AUTOSAR XML (schema 4-0-3)
package /ComponentTypes
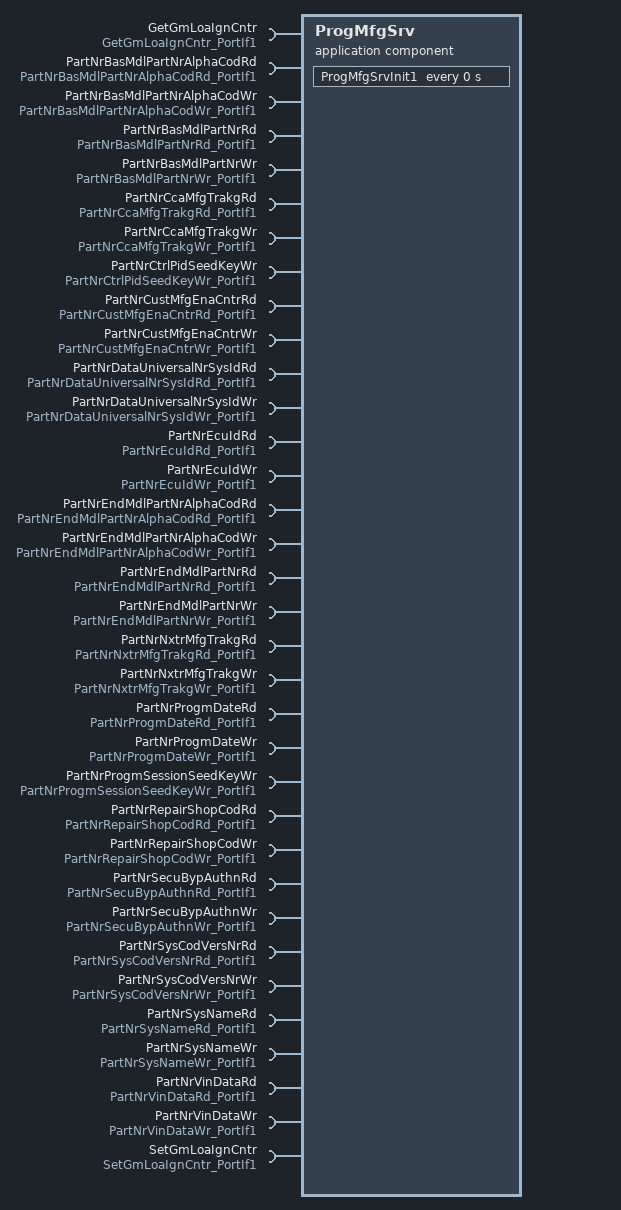
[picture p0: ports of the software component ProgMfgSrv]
  application sw component type ProgMfgSrv
    34 x require port:
      GetGmLoaIgnCntr: required-interface=GetGmLoaIgnCntr_PortIf1
      PartNrBasMdlPartNrAlphaCodRd: required-interface=PartNrBasMdlPartNrAlphaCodRd_PortIf1
      PartNrBasMdlPartNrAlphaCodWr: required-interface=PartNrBasMdlPartNrAlphaCodWr_PortIf1
      PartNrBasMdlPartNrRd: required-interface=PartNrBasMdlPartNrRd_PortIf1
      PartNrBasMdlPartNrWr: required-interface=PartNrBasMdlPartNrWr_PortIf1
      PartNrCcaMfgTrakgRd: required-interface=PartNrCcaMfgTrakgRd_PortIf1
      PartNrCcaMfgTrakgWr: required-interface=PartNrCcaMfgTrakgWr_PortIf1
      PartNrCtrlPidSeedKeyWr: required-interface=PartNrCtrlPidSeedKeyWr_PortIf1
      PartNrCustMfgEnaCntrRd: required-interface=PartNrCustMfgEnaCntrRd_PortIf1
      PartNrCustMfgEnaCntrWr: required-interface=PartNrCustMfgEnaCntrWr_PortIf1
      PartNrDataUniversalNrSysIdRd: required-interface=PartNrDataUniversalNrSysIdRd_PortIf1
      PartNrDataUniversalNrSysIdWr: required-interface=PartNrDataUniversalNrSysIdWr_PortIf1
      PartNrEcuIdRd: required-interface=PartNrEcuIdRd_PortIf1
      PartNrEcuIdWr: required-interface=PartNrEcuIdWr_PortIf1
      PartNrEndMdlPartNrAlphaCodRd: required-interface=PartNrEndMdlPartNrAlphaCodRd_PortIf1
      PartNrEndMdlPartNrAlphaCodWr: required-interface=PartNrEndMdlPartNrAlphaCodWr_PortIf1
      PartNrEndMdlPartNrRd: required-interface=PartNrEndMdlPartNrRd_PortIf1
      PartNrEndMdlPartNrWr: required-interface=PartNrEndMdlPartNrWr_PortIf1
      PartNrNxtrMfgTrakgRd: required-interface=PartNrNxtrMfgTrakgRd_PortIf1
      PartNrNxtrMfgTrakgWr: required-interface=PartNrNxtrMfgTrakgWr_PortIf1
      PartNrProgmDateRd: required-interface=PartNrProgmDateRd_PortIf1
      PartNrProgmDateWr: required-interface=PartNrProgmDateWr_PortIf1
      PartNrProgmSessionSeedKeyWr: required-interface=PartNrProgmSessionSeedKeyWr_PortIf1
      PartNrRepairShopCodRd: required-interface=PartNrRepairShopCodRd_PortIf1
      PartNrRepairShopCodWr: required-interface=PartNrRepairShopCodWr_PortIf1
      PartNrSecuBypAuthnRd: required-interface=PartNrSecuBypAuthnRd_PortIf1
      PartNrSecuBypAuthnWr: required-interface=PartNrSecuBypAuthnWr_PortIf1
      PartNrSysCodVersNrRd: required-interface=PartNrSysCodVersNrRd_PortIf1
      PartNrSysCodVersNrWr: required-interface=PartNrSysCodVersNrWr_PortIf1
      PartNrSysNameRd: required-interface=PartNrSysNameRd_PortIf1
      PartNrSysNameWr: required-interface=PartNrSysNameWr_PortIf1
      PartNrVinDataRd: required-interface=PartNrVinDataRd_PortIf1
      PartNrVinDataWr: required-interface=PartNrVinDataWr_PortIf1
      SetGmLoaIgnCntr: required-interface=SetGmLoaIgnCntr_PortIf1
    behavior ProgMfgSrv_InternalBehavior
      timing event PartNrPer1_InitEvent: start-on-event=ProgMfgSrvInit1, period=0
      runnable ProgMfgSrvInit1
        34 x sync call, all with timeout=0:
          SC_GetGmLoaIgnCntr_Oper: operation=GetGmLoaIgnCntr.Oper
          SC_PartNrBasMdlPartNrAlphaCodRd_Oper: operation=PartNrBasMdlPartNrAlphaCodRd.Oper
          SC_PartNrBasMdlPartNrAlphaCodWr_Oper: operation=PartNrBasMdlPartNrAlphaCodWr.Oper
          SC_PartNrBasMdlPartNrRd_Oper: operation=PartNrBasMdlPartNrRd.Oper
          SC_PartNrBasMdlPartNrWr_Oper: operation=PartNrBasMdlPartNrWr.Oper
          SC_PartNrCcaMfgTrakgRd_Oper: operation=PartNrCcaMfgTrakgRd.Oper
          SC_PartNrCcaMfgTrakgWr_Oper: operation=PartNrCcaMfgTrakgWr.Oper
          SC_PartNrCtrlPidSeedKeyWr_Oper: operation=PartNrCtrlPidSeedKeyWr.Oper
          SC_PartNrCustMfgEnaCntrRd_Oper: operation=PartNrCustMfgEnaCntrRd.Oper
          SC_PartNrCustMfgEnaCntrWr_Oper: operation=PartNrCustMfgEnaCntrWr.Oper
          SC_PartNrDataUniversalNrSysIdRd_Oper: operation=PartNrDataUniversalNrSysIdRd.Oper
          SC_PartNrDataUniversalNrSysIdWr_Oper: operation=PartNrDataUniversalNrSysIdWr.Oper
          SC_PartNrEcuIdRd_Oper: operation=PartNrEcuIdRd.Oper
          SC_PartNrEcuIdWr_Oper: operation=PartNrEcuIdWr.Oper
          SC_PartNrEndMdlPartNrAlphaCodRd_Oper: operation=PartNrEndMdlPartNrAlphaCodRd.Oper
          SC_PartNrEndMdlPartNrAlphaCodWr_Oper: operation=PartNrEndMdlPartNrAlphaCodWr.Oper
          SC_PartNrEndMdlPartNrRd_Oper: operation=PartNrEndMdlPartNrRd.Oper
          SC_PartNrEndMdlPartNrWr_Oper: operation=PartNrEndMdlPartNrWr.Oper
          SC_PartNrNxtrMfgTrakgRd_Oper: operation=PartNrNxtrMfgTrakgRd.Oper
          SC_PartNrNxtrMfgTrakgWr_Oper: operation=PartNrNxtrMfgTrakgWr.Oper
          SC_PartNrProgmDateRd_Oper: operation=PartNrProgmDateRd.Oper
          SC_PartNrProgmDateWr_Oper: operation=PartNrProgmDateWr.Oper
          SC_PartNrProgmSessionSeedKeyWr_Oper: operation=PartNrProgmSessionSeedKeyWr.Oper
          SC_PartNrRepairShopCodRd_Oper: operation=PartNrRepairShopCodRd.Oper
          SC_PartNrRepairShopCodWr_Oper: operation=PartNrRepairShopCodWr.Oper
          SC_PartNrSecuBypAuthnRd_Oper: operation=PartNrSecuBypAuthnRd.Oper
          SC_PartNrSecuBypAuthnWr_Oper: operation=PartNrSecuBypAuthnWr.Oper
          SC_PartNrSysCodVersNrRd_Oper: operation=PartNrSysCodVersNrRd.Oper
          SC_PartNrSysCodVersNrWr_Oper: operation=PartNrSysCodVersNrWr.Oper
          SC_PartNrSysNameRd_Oper: operation=PartNrSysNameRd.Oper
          SC_PartNrSysNameWr_Oper: operation=PartNrSysNameWr.Oper
          SC_PartNrVinDataRd_Oper: operation=PartNrVinDataRd.Oper
          SC_PartNrVinDataWr_Oper: operation=PartNrVinDataWr.Oper
          SC_SetGmLoaIgnCntr_Oper: operation=SetGmLoaIgnCntr.Oper
  swc implementation ProgMfgSrv_Implementation: behavior=ProgMfgSrv_InternalBehavior
    code-descriptors:
      code Default: artifact-descriptors=autosar-engineering-object={short-label=Default, category=SWSRC}
